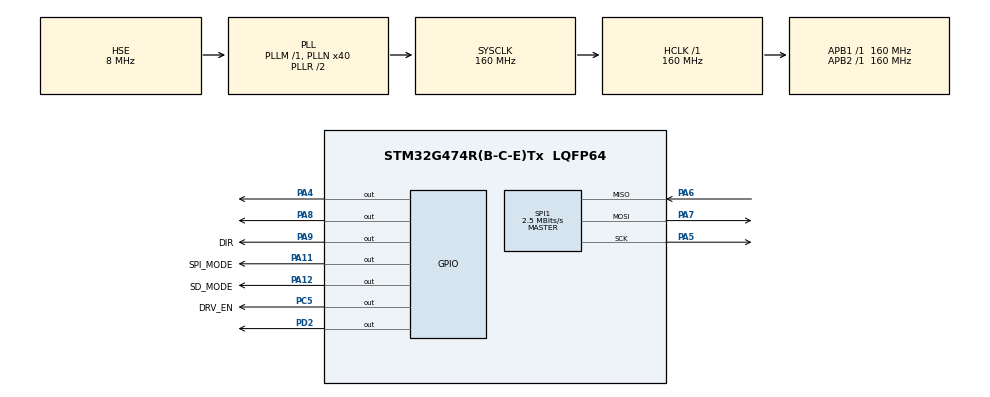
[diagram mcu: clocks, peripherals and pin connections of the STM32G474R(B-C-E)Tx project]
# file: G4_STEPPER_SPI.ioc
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Mcu.Family=STM32G4
Mcu.Name=STM32G474R(B-C-E)Tx
Mcu.Package=LQFP64
NVIC.PriorityGroup=NVIC_PRIORITYGROUP_4
PA11.GPIO_Label=SPI_MODE
PA11.Signal=GPIO_Output
PA12.GPIO_Label=SD_MODE
PA12.Signal=GPIO_Output
PA13.Mode=Serial_Wire
PA13.Signal=SYS_JTMS-SWDIO
PA14.Mode=Serial_Wire
PA14.Signal=SYS_JTCK-SWCLK
PA4.Signal=GPIO_Output
PA5.GPIO_PuPd=GPIO_PULLUP
PA5.GPIO_Speed=GPIO_SPEED_FREQ_MEDIUM
PA5.Mode=Full_Duplex_Master
PA5.Signal=SPI1_SCK
PA6.GPIO_PuPd=GPIO_NOPULL
PA6.GPIO_Speed=GPIO_SPEED_FREQ_MEDIUM
PA6.Mode=Full_Duplex_Master
PA6.Signal=SPI1_MISO
PA7.GPIO_PuPd=GPIO_NOPULL
PA7.GPIO_Speed=GPIO_SPEED_FREQ_MEDIUM
PA7.Mode=Full_Duplex_Master
PA7.Signal=SPI1_MOSI
PA8.Signal=GPIO_Output
PA9.GPIO_Label=DIR
PA9.Signal=GPIO_Output
PC5.GPIO_Label=DRV_EN
PC5.Signal=GPIO_Output
PD2.Signal=GPIO_Output
PF0-OSC_IN.Mode=HSE-External-Oscillator
PF0-OSC_IN.Signal=RCC_OSC_IN
PF1-OSC_OUT.Mode=HSE-External-Oscillator
PF1-OSC_OUT.Signal=RCC_OSC_OUT
ProjectManager.HeapSize=0x200
ProjectManager.StackSize=0x400
ProjectManager.TargetToolchain=STM32CubeIDE
RCC.ADC12Freq_Value=160000000
RCC.ADC345Freq_Value=160000000
RCC.AHBFreq_Value=160000000
RCC.APB1Freq_Value=160000000
RCC.APB1TimFreq_Value=160000000
RCC.APB2Freq_Value=160000000
RCC.APB2TimFreq_Value=160000000
RCC.CortexFreq_Value=160000000
RCC.EXTERNAL_CLOCK_VALUE=12288000
RCC.HCLKFreq_Value=160000000
RCC.HSE_VALUE=8000000
RCC.HSI48_VALUE=48000000
RCC.HSI_VALUE=16000000
RCC.LSE_VALUE=32768
RCC.PLLN=40
RCC.PLLSourceVirtual=RCC_PLLSOURCE_HSE
RCC.SYSCLKFreq_VALUE=160000000
RCC.SYSCLKSource=RCC_SYSCLKSOURCE_PLLCLK
RCC.USBFreq_Value=160000000
RCC.VCOOutputFreq_Value=320000000
SPI1.BaudRatePrescaler=SPI_BAUDRATEPRESCALER_64
SPI1.CLKPhase=SPI_PHASE_2EDGE
SPI1.CLKPolarity=SPI_POLARITY_HIGH
SPI1.CalculateBaudRate=2.5 MBits/s
SPI1.DataSize=SPI_DATASIZE_8BIT
SPI1.Direction=SPI_DIRECTION_2LINES
SPI1.FirstBit=SPI_FIRSTBIT_MSB
SPI1.Mode=SPI_MODE_MASTER
SPI1.VirtualType=VM_MASTER
VP_SYS_VS_DBSignals.Mode=DisableDeadBatterySignals
board=custom

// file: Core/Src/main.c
/* USER CODE BEGIN Header */
/**
  ******************************************************************************
  * @file           : main.c
  * @brief          : Main program body
  ******************************************************************************
  * @attention
  *
  * Copyright (c) 2023 STMicroelectronics.
  * All rights reserved.
  *
  * This software is licensed under terms that can be found in the LICENSE file
  * in the root directory of this software component.
  * If no LICENSE file comes with this software, it is provided AS-IS.
  *
  ******************************************************************************
  */
/* USER CODE END Header */
#include "main.h"
#include "spi.h"
#include "gpio.h"

/* USER CODE BEGIN Includes */

#include <tmc5160.h>
/* USER CODE END Includes */

void SystemClock_Config(void);
/* USER CODE BEGIN PFP */

/*
 * Limits for w  (10<w<100)
 */
/* USER CODE END PFP */

int main(void)
{

  /* MCU Configuration--------------------------------------------------------*/

  /* Reset of all peripherals, Initializes the Flash interface and the Systick. */
  HAL_Init();

  /* Configure the system clock */
  SystemClock_Config();

  /* Initialize all configured peripherals */
  MX_GPIO_Init();
  MX_SPI1_Init();

  /* Infinite loop */
  /* USER CODE BEGIN WHILE */

  tmc5160_init();

  //pick rotation direction, forward by default
  //tmc5160_set_forward_motor_direction();
  //tmc5160_set_inverse_motor_direction();

while (1)
{

tmc5160_position(10000);
HAL_Delay(1000);
tmc5160_set_zero();
HAL_Delay(1000);
    /* USER CODE END WHILE */

  }
}

void SystemClock_Config(void)
{
  RCC_OscInitTypeDef RCC_OscInitStruct = {0};
  RCC_ClkInitTypeDef RCC_ClkInitStruct = {0};

  /** Configure the main internal regulator output voltage
  */
  HAL_PWREx_ControlVoltageScaling(PWR_REGULATOR_VOLTAGE_SCALE1_BOOST);

  /** Initializes the RCC Oscillators according to the specified parameters
  * in the RCC_OscInitTypeDef structure.
  */
  RCC_OscInitStruct.OscillatorType = RCC_OSCILLATORTYPE_HSE;
  RCC_OscInitStruct.HSEState = RCC_HSE_ON;
  RCC_OscInitStruct.PLL.PLLState = RCC_PLL_ON;
  RCC_OscInitStruct.PLL.PLLSource = RCC_PLLSOURCE_HSE;
  RCC_OscInitStruct.PLL.PLLM = RCC_PLLM_DIV1;
  RCC_OscInitStruct.PLL.PLLN = 40;
  RCC_OscInitStruct.PLL.PLLP = RCC_PLLP_DIV2;
  RCC_OscInitStruct.PLL.PLLQ = RCC_PLLQ_DIV2;
  RCC_OscInitStruct.PLL.PLLR = RCC_PLLR_DIV2;
  if (HAL_RCC_OscConfig(&RCC_OscInitStruct) != HAL_OK)
  {
    Error_Handler();
  }

  /** Initializes the CPU, AHB and APB buses clocks
  */
  RCC_ClkInitStruct.ClockType = RCC_CLOCKTYPE_HCLK|RCC_CLOCKTYPE_SYSCLK
                              |RCC_CLOCKTYPE_PCLK1|RCC_CLOCKTYPE_PCLK2;
  RCC_ClkInitStruct.SYSCLKSource = RCC_SYSCLKSOURCE_PLLCLK;
  RCC_ClkInitStruct.AHBCLKDivider = RCC_SYSCLK_DIV1;
  RCC_ClkInitStruct.APB1CLKDivider = RCC_HCLK_DIV1;
  RCC_ClkInitStruct.APB2CLKDivider = RCC_HCLK_DIV1;

  if (HAL_RCC_ClockConfig(&RCC_ClkInitStruct, FLASH_LATENCY_4) != HAL_OK)
  {
    Error_Handler();
  }
}

void Error_Handler(void)
{
  __disable_irq();
  while (1)
  {
  }
}
